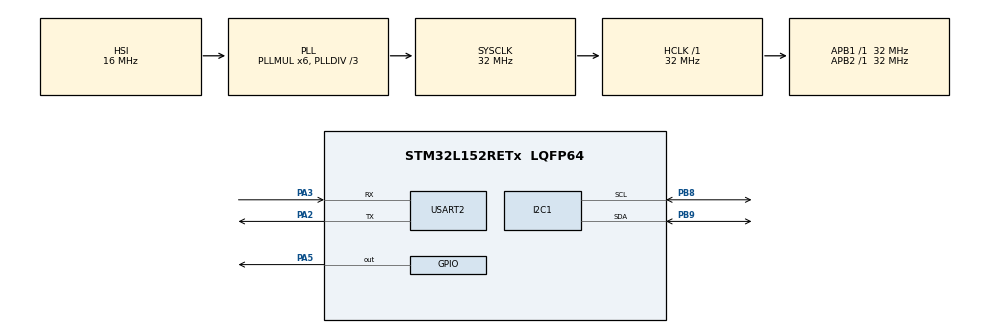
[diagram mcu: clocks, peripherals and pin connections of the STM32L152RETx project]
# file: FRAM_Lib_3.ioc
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Mcu.Family=STM32L1
Mcu.Name=STM32L152RETx
Mcu.Package=LQFP64
NVIC.PriorityGroup=NVIC_PRIORITYGROUP_0
PA2.Mode=Asynchronous
PA2.Signal=USART2_TX
PA3.Mode=Asynchronous
PA3.Signal=USART2_RX
PA5.Signal=GPIO_Output
PB8.Mode=I2C
PB8.Signal=I2C1_SCL
PB9.Mode=I2C
PB9.Signal=I2C1_SDA
ProjectManager.HeapSize=0x200
ProjectManager.StackSize=0x400
ProjectManager.TargetToolchain=MDK-ARM V5
RCC.48MHZClocksFreq_Value=48000000
RCC.AHBFreq_Value=32000000
RCC.APB1Freq_Value=32000000
RCC.APB1TimFreq_Value=32000000
RCC.APB2Freq_Value=32000000
RCC.APB2TimFreq_Value=32000000
RCC.HCLKFreq_Value=32000000
RCC.HSE_VALUE=8000000
RCC.HSI_VALUE=16000000
RCC.LSE_VALUE=32768
RCC.MSI_VALUE=2097000
RCC.PLLDIV=RCC_PLL_DIV3
RCC.PLLMUL=RCC_PLL_MUL6
RCC.RTCClockSelectionVirtual=RCC_RTCCLKSOURCE_LSE
RCC.SYSCLKFreq_VALUE=32000000
RCC.SYSCLKSource=RCC_SYSCLKSOURCE_PLLCLK
RCC.USBOutput=48000000
RCC.VCOOutputFreq_Value=96000000
USART2.VirtualMode=VM_ASYNC
board=NUCLEO-L152RE

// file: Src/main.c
/* USER CODE BEGIN Header */
/**
  ******************************************************************************
  * @file           : main.c
  * @brief          : Main program body
  ******************************************************************************
  ** This notice applies to any and all portions of this file
  * that are not between comment pairs USER CODE BEGIN and
  * USER CODE END. Other portions of this file, whether
  * inserted by the user or by software development tools
  * are owned by their respective copyright owners.
  *
  * COPYRIGHT(c) 2019 STMicroelectronics
  *
  * Redistribution and use in source and binary forms, with or without modification,
  * are permitted provided that the following conditions are met:
  *   1. Redistributions of source code must retain the above copyright notice,
  *      this list of conditions and the following disclaimer.
  *   2. Redistributions in binary form must reproduce the above copyright notice,
  *      this list of conditions and the following disclaimer in the documentation
  *      and/or other materials provided with the distribution.
  *   3. Neither the name of STMicroelectronics nor the names of its contributors
  *      may be used to endorse or promote products derived from this software
  *      without specific prior written permission.
  *
  * THIS SOFTWARE IS PROVIDED BY THE COPYRIGHT HOLDERS AND CONTRIBUTORS "AS IS"
  * AND ANY EXPRESS OR IMPLIED WARRANTIES, INCLUDING, BUT NOT LIMITED TO, THE
  * IMPLIED WARRANTIES OF MERCHANTABILITY AND FITNESS FOR A PARTICULAR PURPOSE ARE
  * DISCLAIMED. IN NO EVENT SHALL THE COPYRIGHT HOLDER OR CONTRIBUTORS BE LIABLE
  * FOR ANY DIRECT, INDIRECT, INCIDENTAL, SPECIAL, EXEMPLARY, OR CONSEQUENTIAL
  * DAMAGES (INCLUDING, BUT NOT LIMITED TO, PROCUREMENT OF SUBSTITUTE GOODS OR
  * SERVICES; LOSS OF USE, DATA, OR PROFITS; OR BUSINESS INTERRUPTION) HOWEVER
  * CAUSED AND ON ANY THEORY OF LIABILITY, WHETHER IN CONTRACT, STRICT LIABILITY,
  * OR TORT (INCLUDING NEGLIGENCE OR OTHERWISE) ARISING IN ANY WAY OUT OF THE USE
  * OF THIS SOFTWARE, EVEN IF ADVISED OF THE POSSIBILITY OF SUCH DAMAGE.
  *
  ******************************************************************************
  */
/* USER CODE END Header */

#include "main.h"

/* USER CODE BEGIN Includes */
#include "FRAM_Lib.h"
#include "FRAM_Tests.h"

/* USER CODE END Includes */

I2C_HandleTypeDef hi2c1;

UART_HandleTypeDef huart2;

void SystemClock_Config(void);
static void MX_GPIO_Init(void);
static void MX_I2C1_Init(void);
static void MX_USART2_UART_Init(void);

int main(void)
{

  /* MCU Configuration--------------------------------------------------------*/

  /* Reset of all peripherals, Initializes the Flash interface and the Systick. */
  HAL_Init();

  /* Configure the system clock */
  SystemClock_Config();

  /* Initialize all configured peripherals */
  MX_GPIO_Init();
  MX_I2C1_Init();
  MX_USART2_UART_Init();

  /* Infinite loop */
  while (1)
  {

    /* USER CODE BEGIN 3 */

		  FRAM_Test(&hi2c1, &huart2);
//		uint8_t Start[22] = "Start(): \r\n";
//		uint8_t Success[22] = "Success\r\n";
//		uint8_t Failure[22] = "Failure\r\n";
//		HAL_UART_Transmit(&huart2,Start,11,10);

//		volatile  uint64_t testData = 0;
//		volatile  uint64_t retrival = 0;

//		testData = 0x123456789ABCDEF0;

//		Store_Time(&hi2c1, 0, 0xFFFF, testData,&huart2);
//		HAL_UART_Transmit(&huart2,Start,11,10);
//		retrival = Retrieve_Time(&hi2c1, 0, 0xFFFF,&huart2);
//
//		uint8_t output[30] = {0};
//		sprintf(output,"%016x\n",retrival);
//		HAL_UART_Transmit(&huart2,output,20,10);
//
//		if(testData == retrival){
//			HAL_UART_Transmit(&huart2,Success,9,10);
//		}else{
//			HAL_UART_Transmit(&huart2,Failure,9,10);
//		}
//
		while(1);

		//HAL_I2C_Mem_Write(&hi2c1, 0xA0 | (0 << 1) + 1, 0xFFFF, 0x08, testData, 1, 10);

  }
  /* USER CODE END 3 */
}

void SystemClock_Config(void)
{
  RCC_OscInitTypeDef RCC_OscInitStruct = {0};
  RCC_ClkInitTypeDef RCC_ClkInitStruct = {0};

  /**Configure the main internal regulator output voltage
  */
  __HAL_PWR_VOLTAGESCALING_CONFIG(PWR_REGULATOR_VOLTAGE_SCALE1);
  /**Initializes the CPU, AHB and APB busses clocks
  */
  RCC_OscInitStruct.OscillatorType = RCC_OSCILLATORTYPE_HSI;
  RCC_OscInitStruct.HSIState = RCC_HSI_ON;
  RCC_OscInitStruct.HSICalibrationValue = RCC_HSICALIBRATION_DEFAULT;
  RCC_OscInitStruct.PLL.PLLState = RCC_PLL_ON;
  RCC_OscInitStruct.PLL.PLLSource = RCC_PLLSOURCE_HSI;
  RCC_OscInitStruct.PLL.PLLMUL = RCC_PLL_MUL6;
  RCC_OscInitStruct.PLL.PLLDIV = RCC_PLL_DIV3;
  if (HAL_RCC_OscConfig(&RCC_OscInitStruct) != HAL_OK)
  {
    Error_Handler();
  }
  /**Initializes the CPU, AHB and APB busses clocks
  */
  RCC_ClkInitStruct.ClockType = RCC_CLOCKTYPE_HCLK|RCC_CLOCKTYPE_SYSCLK
                              |RCC_CLOCKTYPE_PCLK1|RCC_CLOCKTYPE_PCLK2;
  RCC_ClkInitStruct.SYSCLKSource = RCC_SYSCLKSOURCE_PLLCLK;
  RCC_ClkInitStruct.AHBCLKDivider = RCC_SYSCLK_DIV1;
  RCC_ClkInitStruct.APB1CLKDivider = RCC_HCLK_DIV1;
  RCC_ClkInitStruct.APB2CLKDivider = RCC_HCLK_DIV1;

  if (HAL_RCC_ClockConfig(&RCC_ClkInitStruct, FLASH_LATENCY_1) != HAL_OK)
  {
    Error_Handler();
  }
}

static void MX_I2C1_Init(void)
{

  hi2c1.Instance = I2C1;
  hi2c1.Init.ClockSpeed = 100000;
  hi2c1.Init.DutyCycle = I2C_DUTYCYCLE_2;
  hi2c1.Init.OwnAddress1 = 0;
  hi2c1.Init.AddressingMode = I2C_ADDRESSINGMODE_7BIT;
  hi2c1.Init.DualAddressMode = I2C_DUALADDRESS_DISABLE;
  hi2c1.Init.OwnAddress2 = 0;
  hi2c1.Init.GeneralCallMode = I2C_GENERALCALL_DISABLE;
  hi2c1.Init.NoStretchMode = I2C_NOSTRETCH_DISABLE;
  if (HAL_I2C_Init(&hi2c1) != HAL_OK)
  {
    Error_Handler();
  }

}

static void MX_USART2_UART_Init(void)
{

  huart2.Instance = USART2;
  huart2.Init.BaudRate = 115200;
  huart2.Init.WordLength = UART_WORDLENGTH_8B;
  huart2.Init.StopBits = UART_STOPBITS_1;
  huart2.Init.Parity = UART_PARITY_NONE;
  huart2.Init.Mode = UART_MODE_TX_RX;
  huart2.Init.HwFlowCtl = UART_HWCONTROL_NONE;
  huart2.Init.OverSampling = UART_OVERSAMPLING_16;
  if (HAL_UART_Init(&huart2) != HAL_OK)
  {
    Error_Handler();
  }

}

static void MX_GPIO_Init(void)
{
  GPIO_InitTypeDef GPIO_InitStruct = {0};

  /* GPIO Ports Clock Enable */
  __HAL_RCC_GPIOA_CLK_ENABLE();
  __HAL_RCC_GPIOB_CLK_ENABLE();

  /*Configure GPIO pin Output Level */
  HAL_GPIO_WritePin(GPIOA, GPIO_PIN_5, GPIO_PIN_RESET);

  /*Configure GPIO pin : PA5 */
  GPIO_InitStruct.Pin = GPIO_PIN_5;
  GPIO_InitStruct.Mode = GPIO_MODE_OUTPUT_PP;
  GPIO_InitStruct.Pull = GPIO_NOPULL;
  GPIO_InitStruct.Speed = GPIO_SPEED_FREQ_LOW;
  HAL_GPIO_Init(GPIOA, &GPIO_InitStruct);

}

void Error_Handler(void)
{
}

/************************ (C) COPYRIGHT STMicroelectronics *****END OF FILE****/
